# AVR128DA32 device description
Architecture: AVR8X; Family: AVR; Series: AVR-DA
Registers are 8-bit, read-write, reset 0x0 unless marked. A register's access mark holds for its fields unless they carry their own. Offsets are from the block's base; lines under a group give offsets from that group; [hi:lo] are bit positions; {n}, {i} and the like mark numbered series; 'fields as' and 'values as' point back to an identical list; <NAME> marks a mode.

## Ordering variants
AVR128DA32-I/PT: TQFP32, up to 24 MHz, -40 to +85 C, 1.8 to 5.5 V

## Memory
prog space: start 0x0 size 0x20000, little endian
  0x0 APP_SECTION size 0x20000 flash, ro, executable, page 0x200
data space: start 0x0 size 0x10000, little endian
  0x8000 MAPPED_PROGMEM size 0x8000 other, ro
  0x4000 INTERNAL_SRAM size 0x4000 ram, rw
  0x0000 IO size 0x1000 io, rw
  0x1000 EXT_IO size 0x3000 io, rw
eeprom space: start 0x1400 size 0x200, little endian
  0x1400 EEPROM size 0x200 eeprom, rw, page 0x1
fuses space: start 0x1050 size 0x10, little endian

## Peripheral instances (address, pins/pin function, parameters)
USART0 at 0x800 (USART) — Universal Synchronous/Asynchronous Receiver/Transmitter
  pins: TXD0 PA0; RXD0 PA1
USART1 at 0x820 (USART) — Universal Synchronous/Asynchronous Receiver/Transmitter
  pins: TXD0 PC0; RXD0 PC1
TWI0 at 0x8A0 (TWI) — Two-Wire Interface
  pins: SDA0 PA2; SCL0 PA3
SPI0 at 0x8C0 (SPI) — Serial Peripheral Interface
  pins: MOSI0 PA4; MISO0 PA5; SCK0 PA6; SS0 PA7
TCA0 at 0xA00 (TCA) — 16-bit Timer/Counter Type A
PORTA at 0x400 (PORT) — I/O Ports
PORTC at 0x440 (PORT) — I/O Ports
CLKCTRL at 0x60 — Clock Controller
PORTMUX at 0x200 — Port Multiplexer

## Interrupts
0 RESET — Reset Vector
1 NMI — Non-Maskable Interrupt from CRC
18 USART0_RXC — USART0 Receive complete
19 USART0_DRE — USART0 Data Register Empty
20 USART0_TXC — USART0 Transmit complete
26 TWI0_TWIS — TWI0 Slave
27 TWI0_TWIM — TWI0 Master
28 SPI0_INT — SPI0 Interrupt

## CLKCTRL — Clock Controller
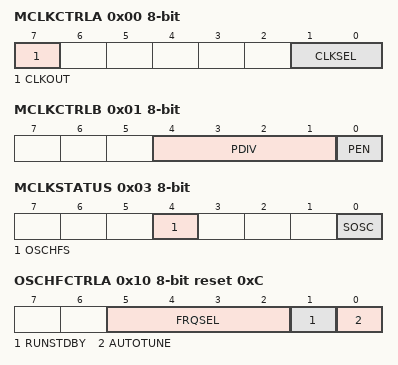
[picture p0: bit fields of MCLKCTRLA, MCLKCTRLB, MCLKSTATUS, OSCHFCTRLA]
0x00 MCLKCTRLA — MCLK Control A
  [7] CLKOUT — System Clock Out
  [1:0] CLKSEL — Clock Select
0x01 MCLKCTRLB — MCLK Control B
  [4:1] PDIV — Prescaler Division
  [0] PEN — Prescaler Enable
0x02 MCLKLOCK
  [0] LOCKEN — Lock Enable
0x03 MCLKSTATUS ro
  [4] OSCHFS — High-Frequency Oscillator Status
  [0] SOSC — System Oscillator Status
0x10 OSCHFCTRLA reset 0xC — OSCHF Control A
  [5:2] FRQSEL — Frequency Select
  [1] RUNSTDBY — Run in Standby
  [0] AUTOTUNE

## USART
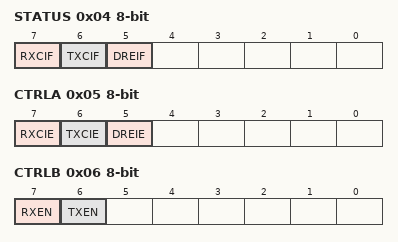
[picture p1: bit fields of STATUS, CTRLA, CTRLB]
0x04 STATUS
  [7] RXCIF — Receive Complete Interrupt Flag
  [6] TXCIF — Transmit Complete Interrupt Flag
  [5] DREIF — Data Register Empty Interrupt Flag
0x05 CTRLA — Control A
  [7] RXCIE — RX Complete Interrupt Enable
  [6] TXCIE — TX Complete Interrupt Enable
  [5] DREIE — Data Register Empty Interrupt Enable
0x06 CTRLB — Control B
  [7] RXEN — Receiver Enable
  [6] TXEN — Transmitter Enable

## TWI
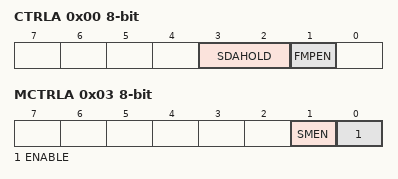
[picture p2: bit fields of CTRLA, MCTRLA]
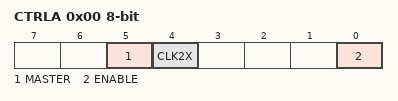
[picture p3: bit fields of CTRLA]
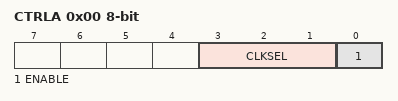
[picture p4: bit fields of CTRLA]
0x00 CTRLA — Control A
  [3:2] SDAHOLD — SDA Hold Time
  [1] FMPEN — Fast Mode Plus Enable
0x03 MCTRLA — Master Control A
  [1] SMEN — Smart Mode Enable
  [0] ENABLE — Enable TWI Master

## SPI
0x00 CTRLA — Control A
  [5] MASTER — Master Select
  [4] CLK2X — Enable Double SPI Speed
  [0] ENABLE — Enable SPI
0x01 CTRLB — Control B
  [2] SSD — Slave Select Disable

## TCA
0x00 CTRLA — Control A
  [3:1] CLKSEL — Clock Select
  [0] ENABLE

## PORT
0x00 DIR — Data Direction
0x04 OUT — Output Value
0x08 IN ro — Input Value

## PORTMUX — Port Multiplexer
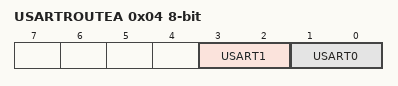
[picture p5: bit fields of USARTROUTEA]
0x04 USARTROUTEA
  [3:2] USART1 — USART1 Route
  [1:0] USART0 — USART0 Route
0x08 SPIROUTEA
  [1:0] SPI0 — SPI0 Route
0x0A TWIROUTEA
  [1:0] TWI0 — TWI0 Route

## Notices in the file
Copyright (c) 2021-2024 Microchip Technology Inc.
SPDX-License-Identifier: Apache-2.0
